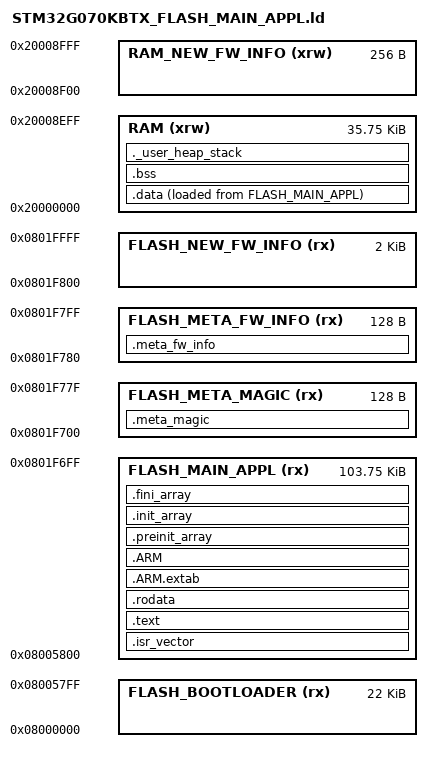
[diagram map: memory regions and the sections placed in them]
/**
 ******************************************************************************
 * @file      LinkerScript.ld
 * @author    Auto-generated by STM32CubeIDE
 * @brief     Linker script for STM32G070KBTx Device from STM32G0 series
 *                      128Kbytes FLASH
 *                      36Kbytes RAM
 *
 *            Set heap size, stack size and stack location according
 *            to application requirements.
 *
 *            Set memory bank area and size if external memory is used
 ******************************************************************************
 * @attention
 *
 * <h2><center>&copy; Copyright (c) 2020 STMicroelectronics.
 * All rights reserved.</center></h2>
 *
 * This software component is licensed by ST under BSD 3-Clause license,
 * the "License"; You may not use this file except in compliance with the
 * License. You may obtain a copy of the License at:
 *                        opensource.org/licenses/BSD-3-Clause
 *
 ******************************************************************************
 */

/* Entry Point */
ENTRY(Reset_Handler)

/* Highest address of the user mode stack */
_estack = ORIGIN(RAM) + LENGTH(RAM);	/* end of "RAM" Ram type memory */

_Min_Heap_Size = 0x400 ;    /* required amount of heap  */
_Min_Stack_Size = 0x800 ;   /* required amount of stack */

__ram_newfwinfo_addr = ORIGIN(RAM_NEW_FW_INFO);
__flash_bootloader_addr = ORIGIN(FLASH_BOOTLOADER);
__flash_mainappl_addr = ORIGIN(FLASH_MAIN_APPL);
__flash_newfwinfo_addr = ORIGIN(FLASH_NEW_FW_INFO);
__flash_mainappl_magic_num_addr = ORIGIN(FLASH_META_MAGIC);

/* Memories definition */
MEMORY
{
  RAM                   (xrw)   : ORIGIN = 0x20000000,   LENGTH = 0x8F00
  RAM_NEW_FW_INFO       (xrw)   : ORIGIN = 0x20008F00,   LENGTH = 0x100     /* address of new fw info for fw upgrade */

  FLASH_BOOTLOADER      (rx)    : ORIGIN = 0x8000000,   LENGTH = 22K /* address of Bootloader */
  
  /* address of Main Appl contents */
  FLASH_MAIN_APPL       (rx)    : ORIGIN = 0x8005800,   LENGTH = 0x19F00
  FLASH_META_MAGIC      (rx)    : ORIGIN = 0x801F700,   LENGTH = 0x80
  FLASH_META_FW_INFO    (rx)    : ORIGIN = 0x801F780,   LENGTH = 0x80
  
  /* address of new fw info for fw upgrade */
  FLASH_NEW_FW_INFO     (rx)	: ORIGIN = 0x801F800,   LENGTH = 2K
}

/* Sections */
SECTIONS
{
  /* The startup code into "FLASH_MAIN_APPL" Rom type memory */   
  .isr_vector :
  {
    . = ALIGN(4);
    KEEP(*(.isr_vector)) /* Startup code */
    . = ALIGN(4);
  } >FLASH_MAIN_APPL

  /* The program code and other data into "FLASH_MAIN_APPL" Rom type memory */
  .text :
  {
    . = ALIGN(4);
    *(.text)           /* .text sections (code) */
    *(.text*)          /* .text* sections (code) */
    *(.glue_7)         /* glue arm to thumb code */
    *(.glue_7t)        /* glue thumb to arm code */
    *(.eh_frame)

    KEEP (*(.init))
    KEEP (*(.fini))

    . = ALIGN(4);
    _etext = .;        /* define a global symbols at end of code */
  } >FLASH_MAIN_APPL

  /* Constant data into "FLASH_MAIN_APPL" Rom type memory */
  .rodata :
  {
    . = ALIGN(4);
    *(.rodata)         /* .rodata sections (constants, strings, etc.) */
    *(.rodata*)        /* .rodata* sections (constants, strings, etc.) */
    . = ALIGN(4);
  } >FLASH_MAIN_APPL

  .ARM.extab   : {
    . = ALIGN(4);
    *(.ARM.extab* .gnu.linkonce.armextab.*)
    . = ALIGN(4);
  } >FLASH_MAIN_APPL

  .ARM : {
    . = ALIGN(4);
    __exidx_start = .;
    *(.ARM.exidx*)
    __exidx_end = .;
    . = ALIGN(4);
  } >FLASH_MAIN_APPL

  .preinit_array     :
  {
    . = ALIGN(4);
    PROVIDE_HIDDEN (__preinit_array_start = .);
    KEEP (*(.preinit_array*))
    PROVIDE_HIDDEN (__preinit_array_end = .);
    . = ALIGN(4);
  } >FLASH_MAIN_APPL

  .init_array :
  {
    . = ALIGN(4);
    PROVIDE_HIDDEN (__init_array_start = .);
    KEEP (*(SORT(.init_array.*)))
    KEEP (*(.init_array*))
    PROVIDE_HIDDEN (__init_array_end = .);
    . = ALIGN(4);
  } >FLASH_MAIN_APPL

  .fini_array :
  {
    . = ALIGN(4);
    PROVIDE_HIDDEN (__fini_array_start = .);
    KEEP (*(SORT(.fini_array.*)))
    KEEP (*(.fini_array*))
    PROVIDE_HIDDEN (__fini_array_end = .);
    . = ALIGN(4);
  } >FLASH_MAIN_APPL

  .meta_magic :
  {
    . = ALIGN(4);
    *(.meta_magic);
    . = ALIGN(4);
  } >FLASH_META_MAGIC
   
  .meta_fw_info :
  {
    . = ALIGN(4);
    *(.meta_fw_info);
    . = ALIGN(4);
  } >FLASH_META_FW_INFO
  
  /* Used by the startup to initialize data */
  _sidata = LOADADDR(.data);

  /* Initialized data sections into "RAM" Ram type memory */
  .data :
  {
    . = ALIGN(4);
    _sdata = .;        /* create a global symbol at data start */
    *(.data)           /* .data sections */
    *(.data*)          /* .data* sections */
    *(.RamFunc)        /* .RamFunc sections */
    *(.RamFunc*)       /* .RamFunc* sections */

    . = ALIGN(4);
    _edata = .;        /* define a global symbol at data end */

  } >RAM AT> FLASH_MAIN_APPL

  /* Uninitialized data section into "RAM" Ram type memory */
  . = ALIGN(4);
  .bss :
  {
    /* This is used by the startup in order to initialize the .bss section */
    _sbss = .;         /* define a global symbol at bss start */
    __bss_start__ = _sbss;
    *(.bss)
    *(.bss*)
    *(COMMON)

    . = ALIGN(4);
    _ebss = .;         /* define a global symbol at bss end */
    __bss_end__ = _ebss;
  } >RAM

  /* User_heap_stack section, used to check that there is enough "RAM" Ram  type memory left */
  ._user_heap_stack :
  {
    . = ALIGN(8);
    PROVIDE ( end = . );
    PROVIDE ( _end = . );
    . = . + _Min_Heap_Size;
    . = . + _Min_Stack_Size;
    . = ALIGN(8);
  } >RAM
   
  /* Remove information from the compiler libraries */
  /DISCARD/ :
  {
    libc.a ( * )
    libm.a ( * )
    libgcc.a ( * )
  }

  .ARM.attributes 0 : { *(.ARM.attributes) }
}
